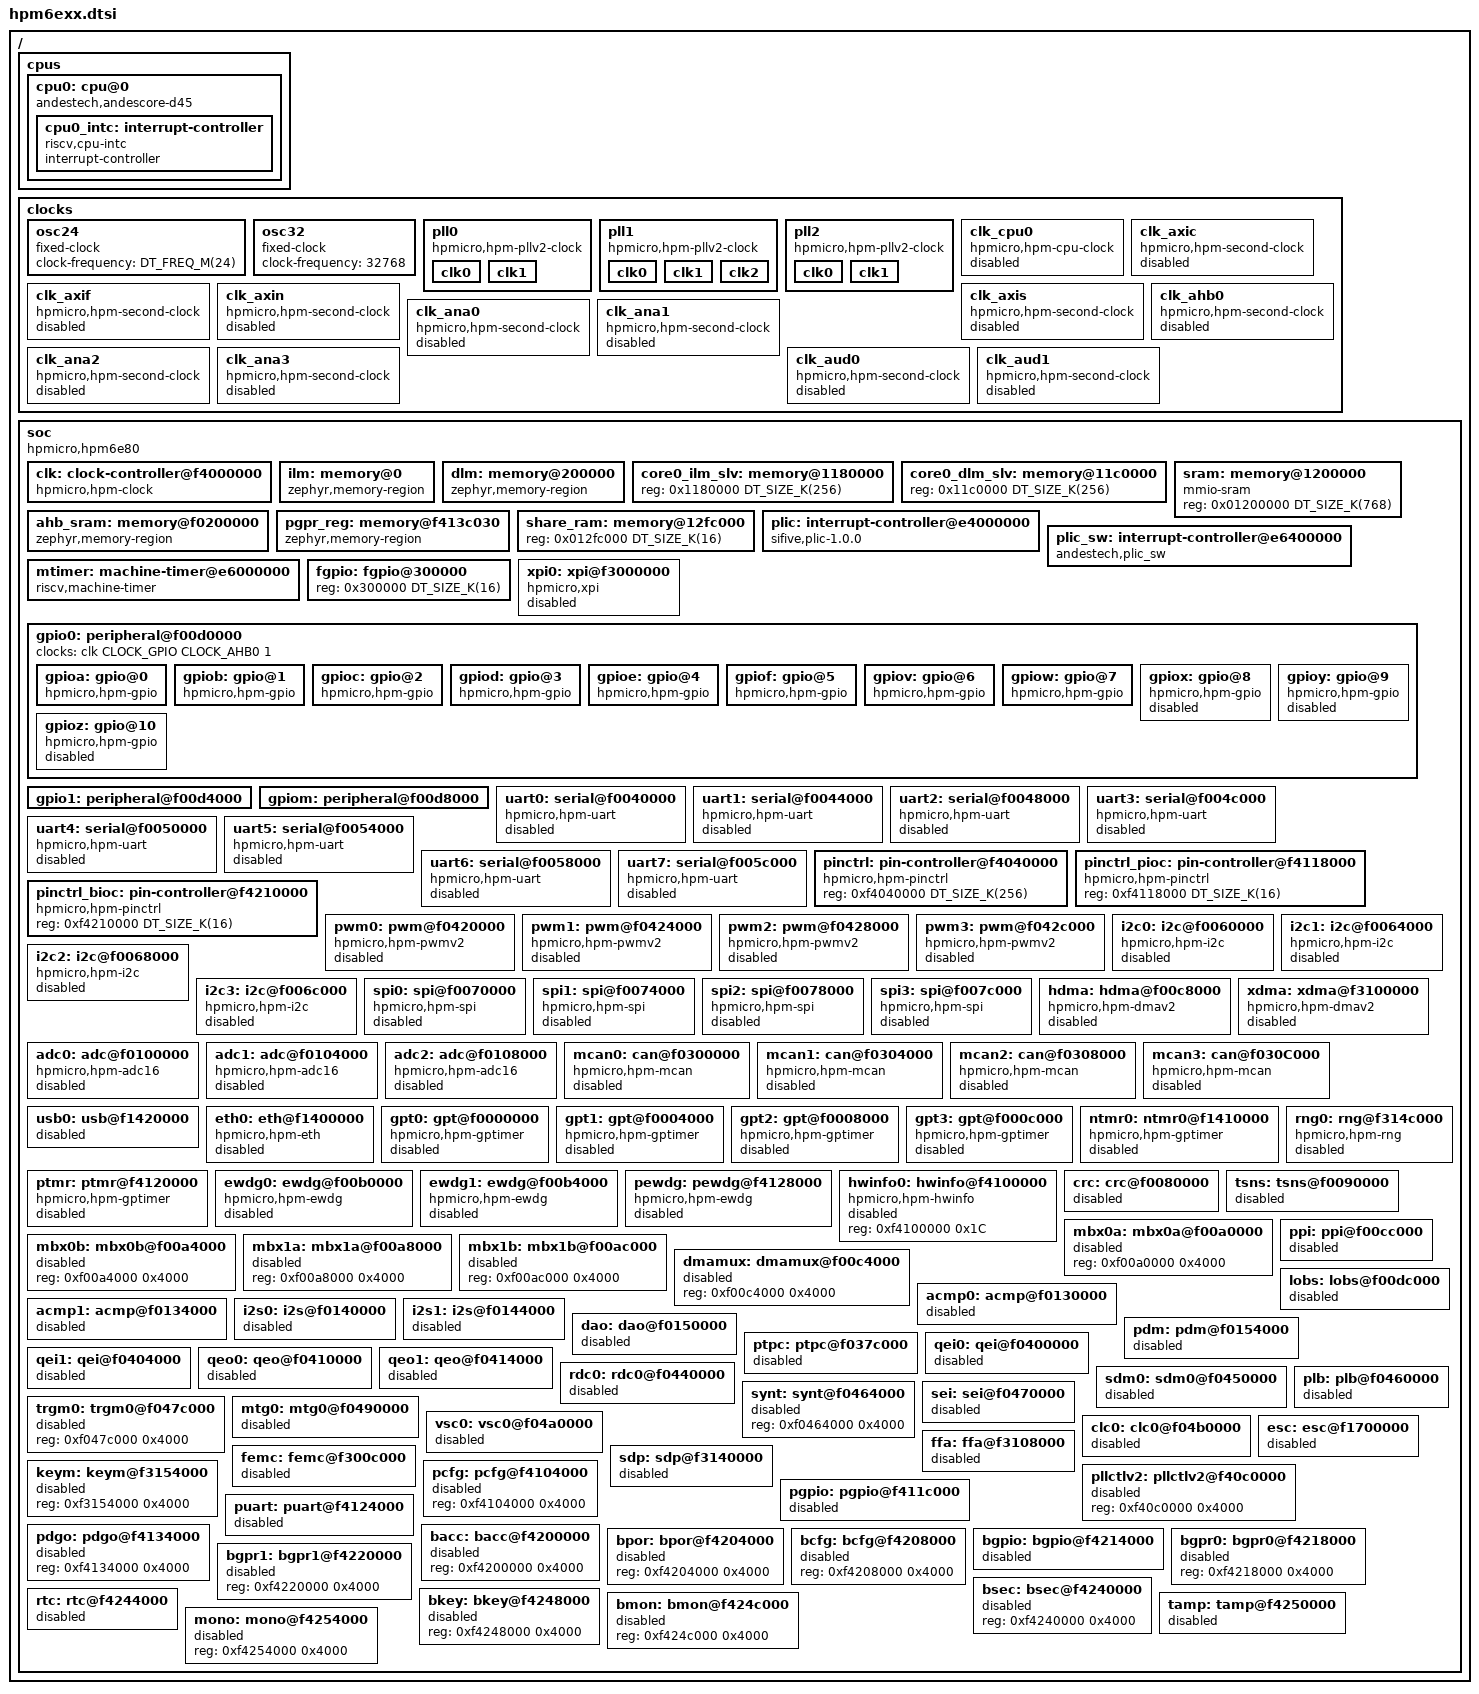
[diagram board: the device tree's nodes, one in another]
/*
* Copyright 2025-2026 HPMicro
* SPDX-License-Identifier: Apache-2.0
*/

/dts-v1/;
#include <zephyr/dt-bindings/gpio/gpio.h>
#include <zephyr/dt-bindings/i2c/i2c.h>
#include <zephyr/dt-bindings/pwm/pwm.h>
#include <dt-bindings/pwm/hpmicro-pwm-common.h>
#include <mem.h>
#include <freq.h>

/ {
	#address-cells = <1>;
	#size-cells = <1>;
	cpus {
		#address-cells = <1>;
		#size-cells = <0>;
		cpu0: cpu@0 {
			compatible = "andestech,andescore-d45", "riscv";
			reg = <0>;
			status = "okay";
			riscv,isa-base = "rv32i";
			riscv,isa-extensions = "i", "m", "a", "c", "f", "d", "b", "p", "zicsr", "zifencei",
				"xandes";
			i-cache-line-size = <64>;
			d-cache-line-size = <64>;
			cpu0_intc: interrupt-controller {
				compatible = "riscv,cpu-intc";
				#address-cells = <0>;
				#interrupt-cells = <1>;
				interrupt-controller;
			};
		};
	};

	clocks {
		osc24: osc24 {
			#clock-cells = <0>;
			compatible = "fixed-clock";
			clock-frequency = <DT_FREQ_M(24)>;
		};

		osc32: osc32 {
			#clock-cells = <0>;
			compatible = "fixed-clock";
			clock-frequency = <32768>;
		};

		pll0: pll0 {
			#clock-cells = <2>;
			compatible = "hpmicro,hpm-pllv2-clock";
			pll-frequency = <DT_FREQ_M(600)>;
			pll-index = <0>;
			clk0 {
				src-name = <CLK_SRC_PLL0_CLK0>;
				div-i = <0>;
				div-p = <0>;
			};

			clk1 {
				src-name = <CLK_SRC_PLL0_CLK1>;
				div-i = <1>;
				div-p = <1>;
			};
		};

		pll1: pll1 {
			#clock-cells = <2>;
			compatible = "hpmicro,hpm-pllv2-clock";
			pll-frequency = <DT_FREQ_M(800)>;
			pll-index = <1>;
			clk0 {
				src-name = <CLK_SRC_PLL1_CLK0>;
				div-i = <0>;
				div-p = <0>;
			};

			clk1 {
				src-name = <CLK_SRC_PLL1_CLK1>;
				div-i = <1>;
				div-p = <7>;
			};

			clk2 {
				src-name = <CLK_SRC_PLL1_CLK2>;
				div-i = <2>;
				div-p = <11>;
			};
		};

		pll2: pll2 {
			#clock-cells = <2>;
			compatible = "hpmicro,hpm-pllv2-clock";
			pll-frequency = <722534400>;
			pll-index = <2>;
			clk0 {
				src-name = <CLK_SRC_PLL2_CLK0>;
				div-i = <0>;
				div-p = <2>;
			};

			clk1 {
				src-name = <CLK_SRC_PLL2_CLK1>;
				div-i = <1>;
				div-p = <3>;
			};
		};

		clk_cpu0: clk_cpu0 {
			#clock-cells = <0>;
			compatible = "hpmicro,hpm-cpu-clock";
			node-name = <CLOCK_CPU0>;
			clocks = <&pll0 0 1>;
			status = "disabled";
		};

		clk_axic: clk_axic {
			#clock-cells = <0>;
			compatible = "hpmicro,hpm-second-clock";
			node-name = <CLOCK_AXIC>;
			clocks = <&pll1 0 4>;
			status = "disabled";
		};

		clk_axif: clk_axif {
			#clock-cells = <0>;
			compatible = "hpmicro,hpm-second-clock";
			node-name = <CLOCK_AXIF>;
			clocks = <&pll1 0 4>;
			status = "disabled";
		};

		clk_axin: clk_axin {
			#clock-cells = <0>;
			compatible = "hpmicro,hpm-second-clock";
			node-name = <CLOCK_AXIN>;
			clocks = <&pll1 0 8>;
			status = "disabled";
		};

		clk_axis: clk_axis {
			#clock-cells = <0>;
			compatible = "hpmicro,hpm-second-clock";
			node-name = <CLOCK_AXIS>;
			clocks = <&pll1 0 4>;
			status = "disabled";
		};

		clk_ahb0: clk_ahb0 {
			#clock-cells = <0>;
			compatible = "hpmicro,hpm-second-clock";
			node-name = <CLOCK_AHB0>;
			clocks = <&pll1 0 4>;
			status = "disabled";
		};

		clk_ana0: clk_ana0 {
			#clock-cells = <0>;
			compatible = "hpmicro,hpm-second-clock";
			node-name = <CLOCK_ANA0>;
			clocks = <&pll1 0 4>;
			status = "disabled";
		};

		clk_ana1: clk_ana1 {
			#clock-cells = <0>;
			compatible = "hpmicro,hpm-second-clock";
			node-name = <CLOCK_ANA1>;
			clocks = <&pll1 0 4>;
			status = "disabled";
		};

		clk_ana2: clk_ana2 {
			#clock-cells = <0>;
			compatible = "hpmicro,hpm-second-clock";
			node-name = <CLOCK_ANA2>;
			clocks = <&pll1 0 4>;
			status = "disabled";
		};

		clk_ana3: clk_ana3 {
			#clock-cells = <0>;
			compatible = "hpmicro,hpm-second-clock";
			node-name = <CLOCK_ANA3>;
			clocks = <&pll1 0 4>;
			status = "disabled";
		};

		clk_aud0: clk_aud0 {
			#clock-cells = <0>;
			compatible = "hpmicro,hpm-second-clock";
			node-name = <CLOCK_AUD0>;
			clocks = <&pll2 0 21>;
			status = "disabled";
		};

		clk_aud1: clk_aud1 {
			#clock-cells = <0>;
			compatible = "hpmicro,hpm-second-clock";
			node-name = <CLOCK_AUD1>;
			clocks = <&pll2 0 21>;
			status = "disabled";
		};
	};

	soc {
		#address-cells = <1>;
		#size-cells = <1>;
		compatible = "hpmicro,hpm6e80";
		ranges;
		clk: clock-controller@f4000000 {
			compatible = "hpmicro,hpm-clock";
			reg = <0xf4000000 DT_SIZE_K(256)
				0xf40c0000 DT_SIZE_K(256)>;
			reg-names = "sysctl", "pllv2";
			status = "okay";
			#clock-cells = <3>;
		};

		ilm: memory@0 {
			compatible = "zephyr,memory-region";
			reg = <0x0 DT_SIZE_K(256)>;
			zephyr,memory-region = "ITCM";
		};

		dlm: memory@200000 {
			compatible = "zephyr,memory-region";
			reg = <0x0200000 DT_SIZE_K(256)>;
			zephyr,memory-region = "DTCM";
		};

		core0_ilm_slv: memory@1180000 {
			reg = <0x1180000 DT_SIZE_K(256)>;
		};

		core0_dlm_slv: memory@11c0000 {
			reg = <0x11c0000 DT_SIZE_K(256)>;
		};

		sram: memory@1200000 {
			compatible = "mmio-sram";
			reg = <0x01200000 DT_SIZE_K(768)>;
		};

		ahb_sram: memory@f0200000 {
			compatible = "zephyr,memory-region";
			reg = <0xf0200000 DT_SIZE_K(32)>;
			zephyr,memory-region = "AHB_SRAM";
		};

		pgpr_reg: memory@f413c030 {
			compatible = "zephyr,memory-region";
			reg = <0xf413c030 16>;
			zephyr,memory-region = "PGPR_REG";
		};

		share_ram: memory@12fc000 {
			reg = <0x012fc000 DT_SIZE_K(16)>;
		};

		plic: interrupt-controller@e4000000 {
			compatible = "sifive,plic-1.0.0";
			#address-cells = <1>;
			#interrupt-cells = <2>;
			interrupt-controller;
			reg = <    0xe4000000 0x00001000
				0xe4002000 0x00000800
				0xe4200000 0x00010000 >;
			reg-names = "prio", "irq_en", "reg";
			riscv,max-priority = <31>;
			riscv,ndev = <162>;
			interrupts-extended = <&cpu0_intc 11>;
		};

		plic_sw: interrupt-controller@e6400000 {
			compatible = "andestech,plic_sw";
			#address-cells = <1>;
			#interrupt-cells = <2>;
			interrupt-controller;
			reg = <0xe6400000 DT_SIZE_M(4)>;
			interrupts-extended = <&cpu0_intc 3>;
		};

		mtimer: machine-timer@e6000000 {
			compatible = "riscv,machine-timer";
			clocks = <&clk CLOCK_MCHTMR0 CLK_SRC_OSC24M 1>;
			reg = <0xe6000000 0x8
				0xe6000008 0x8>;
			reg-names = "mtime", "mtimecmp";
			interrupts-extended = <&cpu0_intc 7>;
		};

		fgpio: fgpio@300000 {
			reg = <0x300000 DT_SIZE_K(16)>;
		};

		xpi0: xpi@f3000000 {
			compatible = "hpmicro,xpi";
			reg = <0xf3000000 DT_SIZE_K(16)>;
			clocks = <&clk CLOCK_XPI0 CLK_SRC_PLL1_CLK1 1>;
			#address-cells = <1>;
			#size-cells = <1>;
			status = "disabled";
		};

		gpio0: peripheral@f00d0000 {
			#address-cells = <1>;
			#size-cells = <1>;
			ranges = <0x0 0xf00d0000 DT_SIZE_K(16)>;
			clocks = <&clk CLOCK_GPIO CLOCK_AHB0 1>;
		};

		gpio1: peripheral@f00d4000 {
			#address-cells = <1>;
			#size-cells = <1>;
			ranges = <0x0 0xf00d4000 DT_SIZE_K(16)>;
		};

		gpiom: peripheral@f00d8000 {
			#address-cells = <1>;
			#size-cells = <1>;
			ranges = <0x0 0xf00d8000 DT_SIZE_K(16)>;
		};

		uart0: serial@f0040000 {
			compatible = "hpmicro,hpm-uart";
			reg = <0xf0040000 DT_SIZE_K(16)>;
			interrupts = <31 1>, <27 1>;
			interrupt-names = "uart", "idletimer";
			clocks = <&clk CLOCK_UART0 CLK_SRC_PLL1_CLK0 10>;
			interrupt-parent = <&plic>;
			status = "disabled";
		};

		uart1: serial@f0044000 {
			compatible = "hpmicro,hpm-uart";
			reg = <0xf0044000 DT_SIZE_K(16)>;
			interrupts = <32 1>, <27 1>;
			interrupt-names = "uart", "idletimer";
			clocks = <&clk CLOCK_UART1 CLK_SRC_PLL1_CLK0 10>;
			interrupt-parent = <&plic>;
			status = "disabled";
		};

		uart2: serial@f0048000 {
			compatible = "hpmicro,hpm-uart";
			reg = <0xf0048000 DT_SIZE_K(16)>;
			interrupts = <33 1>, <27 1>;
			interrupt-names = "uart", "idletimer";
			clocks = <&clk CLOCK_UART2 CLK_SRC_PLL1_CLK0 10>;
			interrupt-parent = <&plic>;
			status = "disabled";
		};

		uart3: serial@f004c000 {
			compatible = "hpmicro,hpm-uart";
			reg = <0xf004c000 DT_SIZE_K(16)>;
			interrupts = <34 1>, <27 1>;
			interrupt-names = "uart", "idletimer";
			clocks = <&clk CLOCK_UART3 CLK_SRC_PLL1_CLK0 10>;
			interrupt-parent = <&plic>;
			status = "disabled";
		};

		uart4: serial@f0050000 {
			compatible = "hpmicro,hpm-uart";
			reg = <0xf0050000 DT_SIZE_K(16)>;
			interrupts = <35 1>, <27 1>;
			interrupt-names = "uart", "idletimer";
			clocks = <&clk CLOCK_UART4 CLK_SRC_PLL1_CLK0 10>;
			interrupt-parent = <&plic>;
			status = "disabled";
		};

		uart5: serial@f0054000 {
			compatible = "hpmicro,hpm-uart";
			reg = <0xf0054000 DT_SIZE_K(16)>;
			interrupts = <36 1>, <27 1>;
			interrupt-names = "uart", "idletimer";
			clocks = <&clk CLOCK_UART5 CLK_SRC_PLL1_CLK0 10>;
			interrupt-parent = <&plic>;
			status = "disabled";
		};

		uart6: serial@f0058000 {
			compatible = "hpmicro,hpm-uart";
			reg = <0xf0058000 DT_SIZE_K(16)>;
			interrupts = <37 1>, <27 1>;
			interrupt-names = "uart", "idletimer";
			clocks = <&clk CLOCK_UART6 CLK_SRC_PLL1_CLK0 10>;
			interrupt-parent = <&plic>;
			status = "disabled";
		};

		uart7: serial@f005c000 {
			compatible = "hpmicro,hpm-uart";
			reg = <0xf005c000 DT_SIZE_K(16)>;
			interrupts = <38 1>, <27 1>;
			interrupt-names = "uart", "idletimer";
			clocks = <&clk CLOCK_UART7 CLK_SRC_PLL1_CLK0 10>;
			interrupt-parent = <&plic>;
			status = "disabled";
		};

		pinctrl: pin-controller@f4040000 {
			compatible = "hpmicro,hpm-pinctrl";
			reg = <0xf4040000 DT_SIZE_K(256)>;
			status = "okay";
		};

		pinctrl_pioc: pin-controller@f4118000 {
			compatible = "hpmicro,hpm-pinctrl";
			reg = <0xf4118000 DT_SIZE_K(16)>;
			status = "okay";
		};

		pinctrl_bioc: pin-controller@f4210000 {
			compatible = "hpmicro,hpm-pinctrl";
			reg = <0xf4210000 DT_SIZE_K(16)>;
			status = "okay";
		};

		pwm0: pwm@f0420000 {
			compatible = "hpmicro,hpm-pwmv2";
			reg = <0xf0420000 DT_SIZE_K(16)>;
			clocks = <&clk CLOCK_PWM0 CLOCK_AHB0 1>;
			status = "disabled";
			#pwm-cells = <3>;
		};

		pwm1: pwm@f0424000 {
			compatible = "hpmicro,hpm-pwmv2";
			reg = <0xf0424000 DT_SIZE_K(16)>;
			clocks = <&clk CLOCK_PWM1 CLOCK_AHB0 1>;
			status = "disabled";
			#pwm-cells = <3>;
		};

		pwm2: pwm@f0428000 {
			compatible = "hpmicro,hpm-pwmv2";
			reg = <0xf0428000 DT_SIZE_K(16)>;
			clocks = <&clk CLOCK_PWM2 CLOCK_AHB0 1>;
			status = "disabled";
			#pwm-cells = <3>;
		};

		pwm3: pwm@f042c000 {
			compatible = "hpmicro,hpm-pwmv2";
			reg = <0xf042c000 DT_SIZE_K(16)>;
			clocks = <&clk CLOCK_PWM3 CLOCK_AHB0 1>;
			status = "disabled";
			#pwm-cells = <3>;
		};

		i2c0: i2c@f0060000 {
			compatible = "hpmicro,hpm-i2c";
			#address-cells = <1>;
			#size-cells = <0>;
			clocks = <&clk CLOCK_I2C0 CLK_SRC_PLL1_CLK0 10>;
			clock-frequency = <I2C_BITRATE_STANDARD>;
			reg = <0xf0060000 DT_SIZE_K(16)>;
			interrupts = <39 1>;
			interrupt-parent = <&plic>;
			status = "disabled";
		};

		i2c1: i2c@f0064000 {
			compatible = "hpmicro,hpm-i2c";
			#address-cells = <1>;
			#size-cells = <0>;
			clocks = <&clk CLOCK_I2C1 CLK_SRC_PLL1_CLK0 10>;
			clock-frequency = <I2C_BITRATE_STANDARD>;
			reg = <0xf0064000 DT_SIZE_K(16)>;
			interrupts = <40 1>;
			interrupt-parent = <&plic>;
			status = "disabled";
		};

		i2c2: i2c@f0068000 {
			compatible = "hpmicro,hpm-i2c";
			#address-cells = <1>;
			#size-cells = <0>;
			clocks = <&clk CLOCK_I2C2 CLK_SRC_PLL1_CLK0 10>;
			clock-frequency = <I2C_BITRATE_STANDARD>;
			reg = <0xf0068000 DT_SIZE_K(16)>;
			interrupts = <41 1>;
			interrupt-parent = <&plic>;
			status = "disabled";
		};

		i2c3: i2c@f006c000 {
			compatible = "hpmicro,hpm-i2c";
			#address-cells = <1>;
			#size-cells = <0>;
			clocks = <&clk CLOCK_I2C3 CLK_SRC_PLL1_CLK0 10>;
			clock-frequency = <I2C_BITRATE_STANDARD>;
			reg = <0xf006c000 DT_SIZE_K(16)>;
			interrupts = <42 1>;
			interrupt-parent = <&plic>;
			status = "disabled";
		};

		spi0: spi@f0070000 {
			compatible = "hpmicro,hpm-spi";
			reg = <0xf0070000 DT_SIZE_K(16)>;
			clocks = <&clk CLOCK_SPI0 CLK_SRC_PLL1_CLK0 10>;
			interrupts = <43 1>;
			interrupt-parent = <&plic>;
			status = "disabled";
			#address-cells = <1>;
			#size-cells = <0>;
			cs-sck-delay = <3>;
			cs-minimum-high-time = <11>;
		};

		spi1: spi@f0074000 {
			compatible = "hpmicro,hpm-spi";
			reg = <0xf0074000 DT_SIZE_K(16)>;
			clocks = <&clk CLOCK_SPI1 CLK_SRC_PLL1_CLK0 10>;
			interrupts = <44 1>;
			interrupt-parent = <&plic>;
			status = "disabled";
			#address-cells = <1>;
			#size-cells = <0>;
			cs-sck-delay = <3>;
			cs-minimum-high-time = <11>;
		};

		spi2: spi@f0078000 {
			compatible = "hpmicro,hpm-spi";
			reg = <0xf0078000 DT_SIZE_K(16)>;
			clocks = <&clk CLOCK_SPI2 CLK_SRC_PLL1_CLK0 10>;
			interrupts = <45 1>;
			interrupt-parent = <&plic>;
			status = "disabled";
			#address-cells = <1>;
			#size-cells = <0>;
			cs-sck-delay = <3>;
			cs-minimum-high-time = <11>;
		};

		spi3: spi@f007c000 {
			compatible = "hpmicro,hpm-spi";
			reg = <0xf007c000 DT_SIZE_K(16)>;
			clocks = <&clk CLOCK_SPI3 CLK_SRC_PLL1_CLK0 10>;
			interrupts = <46 1>;
			interrupt-parent = <&plic>;
			status = "disabled";
			#address-cells = <1>;
			#size-cells = <0>;
			cs-sck-delay = <3>;
			cs-minimum-high-time = <11>;
		};

		hdma: hdma@f00c8000 {
			#dma-cells = <2>;
			compatible = "hpmicro,hpm-dmav2";
			dma-channels = <32>;
			dma-requests = <120>;
			reg = <0xf00c8000 DT_SIZE_K(16)>,
				<0xf00c4000 DT_SIZE_K(16)>; /* DMAMUX base */
				interrupts = <56 1>;
			interrupt-parent = <&plic>;
			clocks = <&clk CLOCK_HDMA CLOCK_AHB0 1>;
			status = "disabled";
		};

		xdma: xdma@f3100000 {
			#dma-cells = <2>;
			compatible = "hpmicro,hpm-dmav2";
			dma-channels = <32>;
			dma-requests = <120>;
			reg = <0xf3100000 DT_SIZE_K(16)>,
				<0xf00c4000 DT_SIZE_K(16)>; /* DMAMUX base */
				interrupts = <140 1>;
			interrupt-parent = <&plic>;
			clocks = <&clk CLOCK_XDMA CLOCK_AXIS 1>;
			status = "disabled";
		};

		adc0: adc@f0100000 {
			compatible = "hpmicro,hpm-adc16";
			reg = <0xf0100000 DT_SIZE_K(16)>;
			interrupts = <58 1>;
			interrupt-parent = <&plic>;
			clocks = <&clk CLOCK_ADC0 CLK_ADC_SRC_AHB0 1>,
				<&clk CLOCK_AHB0 CLK_SRC_PLL1_CLK0 4>;
			adc-clk-div = <4>;
			sample-time = <20>;
			status = "disabled";
			#io-channel-cells = <1>;
		};

		adc1: adc@f0104000 {
			compatible = "hpmicro,hpm-adc16";
			reg = <0xf0104000 DT_SIZE_K(16)>;
			interrupts = <59 1>;
			interrupt-parent = <&plic>;
			clocks = <&clk CLOCK_ADC1 CLK_ADC_SRC_AHB0 1>,
				<&clk CLOCK_AHB0 CLK_SRC_PLL1_CLK0 4>;
			adc-clk-div = <4>;
			sample-time = <20>;
			status = "disabled";
			#io-channel-cells = <1>;
		};

		adc2: adc@f0108000 {
			compatible = "hpmicro,hpm-adc16";
			reg = <0xf0108000 DT_SIZE_K(16)>;
			interrupts = <60 1>;
			interrupt-parent = <&plic>;
			clocks = <&clk CLOCK_ADC2 CLK_ADC_SRC_AHB0 1>,
				<&clk CLOCK_AHB0 CLK_SRC_PLL1_CLK0 4>;
			adc-clk-div = <4>;
			sample-time = <20>;
			status = "disabled";
			#io-channel-cells = <1>;
		};

		mcan0: can@f0300000 {
			compatible = "hpmicro,hpm-mcan";
			reg = <0xf0300000 DT_SIZE_K(16)>;
			interrupts = <90 1>;
			interrupt-parent = <&plic>;
			clocks = <&clk CLOCK_CAN0 CLK_SRC_PLL1_CLK0 10>;
			bitrate = <500000>;
			status = "disabled";
		};

		mcan1: can@f0304000 {
			compatible = "hpmicro,hpm-mcan";
			reg = <0xf0304000 DT_SIZE_K(16)>;
			interrupts = <91 1>;
			interrupt-parent = <&plic>;
			clocks = <&clk CLOCK_CAN1 CLK_SRC_PLL1_CLK0 10>;
			bitrate = <500000>;
			status = "disabled";
		};

		mcan2: can@f0308000 {
			compatible = "hpmicro,hpm-mcan";
			reg = <0xf0308000 DT_SIZE_K(16)>;
			interrupts = <92 1>;
			interrupt-parent = <&plic>;
			clocks = <&clk CLOCK_CAN2 CLK_SRC_PLL1_CLK0 10>;
			bitrate = <500000>;
			status = "disabled";
		};

		mcan3: can@f030C000 {
			compatible = "hpmicro,hpm-mcan";
			reg = <0xf030C000 DT_SIZE_K(16)>;
			interrupts = <93 1>;
			interrupt-parent = <&plic>;
			clocks = <&clk CLOCK_CAN3 CLK_SRC_PLL1_CLK0 10>;
			bitrate = <500000>;
			status = "disabled";
		};

		usb0: usb@f1420000 {
			clk-name = <CLOCK_USB0>;
			reg = <0xf1420000 DT_SIZE_K(16)>;
			interrupts = <127 1>;
			interrupt-parent = <&plic>;
			clocks = <&clk CLOCK_USB0 CLOCK_AXIC 1>;
			num-bidir-endpoints = <8>;
			status = "disabled";
		};

		eth0: eth@f1400000 {
			compatible = "hpmicro,hpm-eth";
			clocks = <&clk CLOCK_ETH0 CLK_SRC_PLL1_CLK2 2>;
			reg = <0xf1400000 DT_SIZE_K(16)>;
			interrupts = <125 1>;
			interrupt-parent = <&plic>;
			status = "disabled";
		};

		gpt0: gpt@f0000000 {
			compatible = "hpmicro,hpm-gptimer";
			reg = <0xf0000000 0x4000>;
			interrupts = <23 1>;
			interrupt-parent = <&plic>;
			gptfreq = <100000000>;
			clocks = <&clk CLOCK_GPTMR0 CLK_SRC_PLL1_CLK0 8>;
			status = "disabled";
		};

		gpt1: gpt@f0004000 {
			compatible = "hpmicro,hpm-gptimer";
			reg = <0xf0004000 0x4000>;
			interrupts = <24 1>;
			interrupt-parent = <&plic>;
			gptfreq = <100000000>;
			clocks = <&clk CLOCK_GPTMR1 CLK_SRC_PLL1_CLK0 8>;
			status = "disabled";
		};

		gpt2: gpt@f0008000 {
			compatible = "hpmicro,hpm-gptimer";
			reg = <0xf0008000 0x4000>;
			interrupts = <25 1>;
			interrupt-parent = <&plic>;
			gptfreq = <100000000>;
			clocks = <&clk CLOCK_GPTMR2 CLK_SRC_PLL1_CLK0 8>;
			status = "disabled";
		};

		gpt3: gpt@f000c000 {
			compatible = "hpmicro,hpm-gptimer";
			reg = <0xf000c000 0x4000>;
			interrupts = <26 1>;
			interrupt-parent = <&plic>;
			gptfreq = <100000000>;
			clocks = <&clk CLOCK_GPTMR3 CLK_SRC_PLL1_CLK0 8>;
			status = "disabled";
		};

		ntmr0: ntmr0@f1410000 {
			compatible = "hpmicro,hpm-gptimer";
			reg = <0xf1410000 0x4000>;
			interrupts = <126 1>;
			interrupt-parent = <&plic>;
			clocks = <&clk CLOCK_NTMR0 CLK_SRC_PLL1_CLK0 8>;
			status = "disabled";
		};

		ptmr: ptmr@f4120000 {
			compatible = "hpmicro,hpm-gptimer";
			reg = <0xf4120000 0x4000>;
			interrupts = <148 1>;
			interrupt-parent = <&plic>;
			clocks = <&clk CLOCK_PTMR CLK_SRC_OSC24M 1>;
			status = "disabled";
		};

		ewdg0: ewdg@f00b0000 {
			compatible = "hpmicro,hpm-ewdg";
			reg = <0xf00b0000 0x4000>;
			interrupts = <52 1>;
			interrupt-parent = <&plic>;
			clocks = <&clk CLOCK_WATCHDOG0 CLK_WDG_SRC_OSC32K 1>;
			reset_none_intr;
			status = "disabled";
		};

		ewdg1: ewdg@f00b4000 {
			compatible = "hpmicro,hpm-ewdg";
			reg = <0xf00b4000 0x4000>;
			interrupts = <53 1>;
			interrupt-parent = <&plic>;
			clocks = <&clk CLOCK_WATCHDOG1 CLK_WDG_SRC_OSC32K 1>;
			reset_none_intr;
			status = "disabled";
		};

		pewdg: pewdg@f4128000 {
			compatible = "hpmicro,hpm-ewdg";
			reg = <0xf4128000 0x4000>;
			interrupts = <147 1>;
			interrupt-parent = <&plic>;
			clocks = <&clk CLOCK_PWDG CLK_PWDG_SRC_OSC32K 1>;
			reset_none_intr;
			status = "disabled";
		};

		hwinfo0: hwinfo@f4100000 {
			compatible = "hpmicro,hpm-hwinfo";
			reg = <0xf4100000 0x1C>;
			status = "disabled";
		};

		rng0: rng@f314c000 {
			compatible = "hpmicro,hpm-rng";
			clk-name = <CLOCK_RNG>;
			clk-source = <0>;
			clk-divider = <0>;
			reg = <0xf314c000 0x4000>;
			interrupts = <143 1>;
			interrupt-parent = <&plic>;
			clocks = <&clk CLOCK_RNG CLOCK_AXIS 1>;
			status = "disabled";
		};

		crc: crc@f0080000 {
			reg = <0xf0080000 0x4000>;
			clocks = <&clk CLOCK_CRC0 CLOCK_AHB0 1>;
			status = "disabled";
		};

		tsns: tsns@f0090000 {
			reg = <0xf0090000 0x4000>;
			clocks = <&clk CLOCK_TSNS CLOCK_AHB0 1>;
			status = "disabled";
		};

		mbx0a: mbx0a@f00a0000 {
			reg = <0xf00a0000 0x4000>;
			status = "disabled";
		};

		mbx0b: mbx0b@f00a4000 {
			reg = <0xf00a4000 0x4000>;
			status = "disabled";
		};

		mbx1a: mbx1a@f00a8000 {
			reg = <0xf00a8000 0x4000>;
			status = "disabled";
		};

		mbx1b: mbx1b@f00ac000 {
			reg = <0xf00ac000 0x4000>;
			status = "disabled";
		};

		dmamux: dmamux@f00c4000 {
			reg = <0xf00c4000 0x4000>;
			status = "disabled";
		};

		ppi: ppi@f00cc000 {
			reg = <0xf00cc000 0x4000>;
			clocks = <&clk CLOCK_PPI0 CLOCK_AHB0 1>;
			status = "disabled";
		};

		lobs: lobs@f00dc000 {
			reg = <0xf00dc000 0x4000>;
			clocks = <&clk CLOCK_LOBS CLOCK_AHB0 1>;
			status = "disabled";
		};

		acmp0: acmp@f0130000 {
			reg = <0xf0130000 0x4000>;
			clocks = <&clk CLOCK_ACMP0 CLOCK_AHB0 1>;
			status = "disabled";
		};

		acmp1: acmp@f0134000 {
			reg = <0xf0134000 0x4000>;
			clocks = <&clk CLOCK_ACMP1 CLOCK_AHB0 1>;
			status = "disabled";
		};

		i2s0: i2s@f0140000 {
			reg = <0xf0140000 0x4000>;
			clocks = <&clk CLOCK_I2S0 CLK_I2S_SRC_AUD0 1>,
				<&clk CLOCK_AUD0 CLK_SRC_PLL2_CLK0 21>;
			status = "disabled";
		};

		i2s1: i2s@f0144000 {
			reg = <0xf0144000 0x4000>;
			clocks = <&clk CLOCK_I2S1 CLK_I2S_SRC_AUD1 1>,
				<&clk CLOCK_AUD1 CLK_SRC_PLL2_CLK0 21>;
			status = "disabled";
		};

		dao: dao@f0150000 {
			reg = <0xf0150000 0x4000>;
			clocks = <&clk CLOCK_DAO CLK_I2S_SRC_AUD1 1>,
				<&clk CLOCK_AUD1 CLK_SRC_PLL2_CLK0 21>;
			status = "disabled";
		};

		pdm: pdm@f0154000 {
			reg = <0xf0154000 0x4000>;
			clocks = <&clk CLOCK_PDM CLK_I2S_SRC_AUD0 1>,
				<&clk CLOCK_AUD0 CLK_SRC_PLL2_CLK0 21>;
			status = "disabled";
		};

		ptpc: ptpc@f037c000 {
			reg = <0xf037c000 0x4000>;
			clocks = <&clk CLOCK_PTPC CLOCK_AHB0 1>;
			status = "disabled";
		};

		qei0: qei@f0400000 {
			reg = <0xf0400000 0x4000>;
			clocks = <&clk CLOCK_QEI0 CLOCK_AHB0 1>;
			status = "disabled";
		};

		qei1: qei@f0404000 {
			reg = <0xf0404000 0x4000>;
			clocks = <&clk CLOCK_QEI1 CLOCK_AHB0 1>;
			status = "disabled";
		};

		qeo0: qeo@f0410000 {
			reg = <0xf0410000 0x4000>;
			clocks = <&clk CLOCK_QEO0 CLOCK_AHB0 1>;
			status = "disabled";
		};

		qeo1: qeo@f0414000 {
			reg = <0xf0414000 0x4000>;
			clocks = <&clk CLOCK_QEO1 CLOCK_AHB0 1>;
			status = "disabled";
		};

		rdc0: rdc0@f0440000 {
			reg = <0xf0440000 0x4000>;
			clocks = <&clk CLOCK_RDC0 CLOCK_AHB0 1>;
			status = "disabled";
		};

		sdm0: sdm0@f0450000 {
			reg = <0xf0450000 0x4000>;
			clocks = <&clk CLOCK_SDM0 CLOCK_AHB0 1>;
			status = "disabled";
		};

		plb: plb@f0460000 {
			reg = <0xf0460000 0x4000>;
			clocks = <&clk CLOCK_PLB0 CLOCK_AHB0 1>;
			status = "disabled";
		};

		synt: synt@f0464000 {
			reg = <0xf0464000 0x4000>;
			status = "disabled";
		};

		sei: sei@f0470000 {
			reg = <0xf0470000 0x4000>;
			clocks = <&clk CLOCK_SEI0 CLOCK_AHB0 1>;
			status = "disabled";
		};

		trgm0: trgm0@f047c000 {
			reg = <0xf047c000 0x4000>;
			status = "disabled";
		};

		mtg0: mtg0@f0490000 {
			reg = <0xf0490000 0x4000>;
			clocks = <&clk CLOCK_MTG0 CLOCK_AHB0 1>;
			status = "disabled";
		};

		vsc0: vsc0@f04a0000 {
			reg = <0xf04a0000 0x4000>;
			clocks = <&clk CLOCK_VSC0 CLOCK_AHB0 1>;
			status = "disabled";
		};

		clc0: clc0@f04b0000 {
			reg = <0xf04b0000 0x4000>;
			clocks = <&clk CLOCK_CLC0 CLOCK_AHB0 1>;
			status = "disabled";
		};

		esc: esc@f1700000 {
			reg = <0xf1700000 0x4000>;
			clocks = <&clk CLOCK_ESC0 CLOCK_AXIN 1>;
			status = "disabled";
		};

		femc: femc@f300c000 {
			reg = <0xf300c000 0x4000>;
			clocks = <&clk CLOCK_FEMC CLK_SRC_PLL1_CLK1 2>;
			status = "disabled";
		};

		ffa: ffa@f3108000 {
			reg = <0xf3108000 0x4000>;
			clocks = <&clk CLOCK_FFA0 CLOCK_AXIS 1>;
			status = "disabled";
		};

		sdp: sdp@f3140000 {
			reg = <0xf3140000 0x4000>;
			clocks = <&clk CLOCK_SDP CLOCK_AXIS 1>;
			status = "disabled";
		};

		keym: keym@f3154000 {
			reg = <0xf3154000 0x4000>;
			status = "disabled";
		};

		pllctlv2: pllctlv2@f40c0000 {
			reg = <0xf40c0000 0x4000>;
			status = "disabled";
		};

		pcfg: pcfg@f4104000 {
			reg = <0xf4104000 0x4000>;
			status = "disabled";
		};

		pgpio: pgpio@f411c000 {
			reg = <0xf411c000 0x4000>;
			clocks = <&osc24>;
			status = "disabled";
		};

		puart: puart@f4124000 {
			reg = <0xf4124000 0x4000>;
			clocks = <&clk CLOCK_PUART CLK_SRC_OSC24M 1>;
			status = "disabled";
		};

		pdgo: pdgo@f4134000 {
			reg = <0xf4134000 0x4000>;
			status = "disabled";
		};

		bacc: bacc@f4200000 {
			reg = <0xf4200000 0x4000>;
			status = "disabled";
		};

		bpor: bpor@f4204000 {
			reg = <0xf4204000 0x4000>;
			status = "disabled";
		};

		bcfg: bcfg@f4208000 {
			reg = <0xf4208000 0x4000>;
			status = "disabled";
		};

		bgpio: bgpio@f4214000 {
			reg = <0xf4214000 0x4000>;
			clocks = <&osc32>;
			status = "disabled";
		};

		bgpr0: bgpr0@f4218000 {
			reg = <0xf4218000 0x4000>;
			status = "disabled";
		};

		bgpr1: bgpr1@f4220000 {
			reg = <0xf4220000 0x4000>;
			status = "disabled";
		};

		bsec: bsec@f4240000 {
			reg = <0xf4240000 0x4000>;
			status = "disabled";
		};

		rtc: rtc@f4244000 {
			reg = <0xf4244000 0x4000>;
			clocks = <&osc32>;
			status = "disabled";
		};

		bkey: bkey@f4248000 {
			reg = <0xf4248000 0x4000>;
			status = "disabled";
		};

		bmon: bmon@f424c000 {
			reg = <0xf424c000 0x4000>;
			status = "disabled";
		};

		tamp: tamp@f4250000 {
			reg = <0xf4250000 0x4000>;
			clocks = <&osc32>;
			status = "disabled";
		};

		mono: mono@f4254000 {
			reg = <0xf4254000 0x4000>;
			status = "disabled";
		};
	};
};

&gpio0 {
	gpioa: gpio@0 {
		compatible = "hpmicro,hpm-gpio";
		reg = <0x0 DT_SIZE_K(16)>;
		gpio-controller;
		#gpio-cells = <2>;
		hpmicro-gpio-port = <0>;
		interrupts = <1 1>;
		interrupt-parent = <&plic>;
	};

	gpiob: gpio@1 {
		compatible = "hpmicro,hpm-gpio";
		reg = <0x0 DT_SIZE_K(16)>;
		gpio-controller;
		#gpio-cells = <2>;
		hpmicro-gpio-port = <1>;
		interrupts = <2 1>;
		interrupt-parent = <&plic>;
	};

	gpioc: gpio@2 {
		compatible = "hpmicro,hpm-gpio";
		reg = <0x0 DT_SIZE_K(16)>;
		gpio-controller;
		#gpio-cells = <2>;
		hpmicro-gpio-port = <2>;
		interrupts = <3 1>;
		interrupt-parent = <&plic>;
	};

	gpiod: gpio@3 {
		compatible = "hpmicro,hpm-gpio";
		reg = <0x0 DT_SIZE_K(16)>;
		gpio-controller;
		#gpio-cells = <2>;
		hpmicro-gpio-port = <3>;
		interrupts = <4 1>;
		interrupt-parent = <&plic>;
	};

	gpioe: gpio@4 {
		compatible = "hpmicro,hpm-gpio";
		reg = <0x0 DT_SIZE_K(16)>;
		gpio-controller;
		#gpio-cells = <2>;
		hpmicro-gpio-port = <4>;
		interrupts = <5 1>;
		interrupt-parent = <&plic>;
	};

	gpiof: gpio@5 {
		compatible = "hpmicro,hpm-gpio";
		reg = <0x0 DT_SIZE_K(16)>;
		gpio-controller;
		#gpio-cells = <2>;
		hpmicro-gpio-port = <5>;
		interrupts = <6 1>;
		interrupt-parent = <&plic>;
	};

	gpiov: gpio@6 {
		compatible = "hpmicro,hpm-gpio";
		reg = <0x0 DT_SIZE_K(16)>;
		gpio-controller;
		#gpio-cells = <2>;
		hpmicro-gpio-port = <6>;
		interrupts = <7 1>;
		interrupt-parent = <&plic>;
	};

	gpiow: gpio@7 {
		compatible = "hpmicro,hpm-gpio";
		reg = <0x0 DT_SIZE_K(16)>;
		gpio-controller;
		#gpio-cells = <2>;
		hpmicro-gpio-port = <7>;
		interrupts = <8 1>;
		interrupt-parent = <&plic>;
	};

	gpiox: gpio@8 {
		compatible = "hpmicro,hpm-gpio";
		reg = <0x0 DT_SIZE_K(16)>;
		gpio-controller;
		#gpio-cells = <2>;
		hpmicro-gpio-port = <8>;
		interrupt-parent = <&plic>;
		interrupts = <9 1>;
		status = "disabled";
	};

	gpioy: gpio@9 {
		compatible = "hpmicro,hpm-gpio";
		reg = <0x0 DT_SIZE_K(16)>;
		gpio-controller;
		#gpio-cells = <2>;
		hpmicro-gpio-port = <9>;
		interrupts = <10 1>;
		interrupt-parent = <&plic>;
		status = "disabled";
	};

	gpioz: gpio@10 {
		compatible = "hpmicro,hpm-gpio";
		reg = <0x0 DT_SIZE_K(16)>;
		gpio-controller;
		#gpio-cells = <2>;
		hpmicro-gpio-port = <10>;
		interrupts = <11 1>;
		interrupt-parent = <&plic>;
		status = "disabled";
	};
};
